# SIM3U167_B register map
File version: 1
CPU: 
Registers are 32-bit, read-write, reset 0x0 unless marked. A register's access mark holds for its fields unless they carry their own. Offsets are from the block's base; [hi:lo] are bit positions; {n}, {i} and the like mark numbered series.

## I2C_0
Base 0x40009000
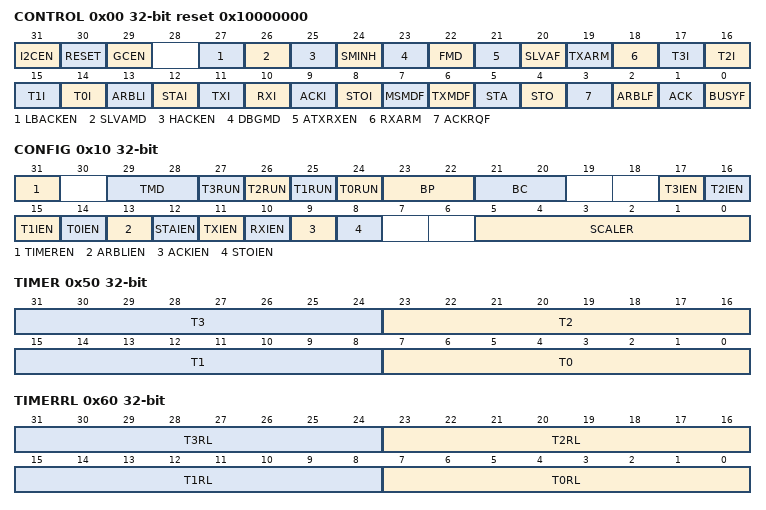
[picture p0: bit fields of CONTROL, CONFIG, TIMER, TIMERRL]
0x00 CONTROL reset 0x10000000 — Module Control
  [31] I2CEN — I2C Enable.
    0=DISABLED (Disable the I2C module.); 1=ENABLED (Enable the I2C module.)
  [30] RESET — Module Soft Reset.
    0=INACTIVE (I2C module is not in soft reset.); 1=ACTIVE (I2C module is in soft reset and firmware cannot access all bits in the module.)
  [29] GCEN — General Call Address Enable.
    0=DISABLED (Disable General Call address decoding.); 1=ENABLED (Enable General Call address decoding.)
  [27] LBACKEN — Last Byte Acknowledge Enable.
    0=DISABLED (NACK after the last byte is received.); 1=ENABLED (ACK after the last byte is received.)
  [26] SLVAMD — Slave Address Mode.
    0=7BIT (Slave addresses are 7 bits.); 1=10BIT (Slave addresses are 10 bits.)
  [25] HACKEN — Auto Acknowledge Enable .
    0=DISABLED (Disable automatic hardware acknowledge.); 1=ENABLED (Enable automatic hardware acknowledge.)
  [24] SMINH — Slave Mode Inhibit.
    0=INACTIVE (Enable Slave modes.); 1=ACTIVE (Inhibit Slave modes. The module will not respond to a Master on the bus.)
  [23] DBGMD — I2C Debug Mode.
    0=RUN (The I2C module will continue to operate while the core is halted in debug mode.); 1=HALT (A debug breakpoint will cause the I2C module to halt.)
  [22] FMD — Filter Mode.
    0=DISABLED (Disable the input filter.); 1=ENABLED (Enable the input filter.)
  [21] ATXRXEN — Auto Transmit or Receive Enable.
    0=DISABLED (Do not automatically switch to transmit or receive mode after a Start.); 1=ENABLED (If automatic hardware acknowledge mode is enabled (HACKEN = 1), automatically switch to transmit or receive mode after a Start.)
  [20] SLVAF ro — Slave Address Type Flag.
    0=SLAVE_ADDRESS (Slave address detected.); 1=GENERAL_CALL (General Call address detected.)
  [19] TXARM — Transmit Arm.
    0=DISABLED (Disable data and address transmission.); 1=ENABLED (Enable the module to perform a transmit operation.)
  [18] RXARM — Receive Arm.
    0=DISABLED (Disable data and address reception.); 1=ENABLED (Enable the module to perform a receive operation.)
  [17] T3I — I2C Timer Byte 3 Interrupt Flag.
    0=NOT_SET (Read: A I2C Timer Byte 3 interrupt or SCL low timeout has not occurred. Write: Clear the I2C Timer Byte 3 interrupt (T3I).); 1=SET (Read: I2C Timer Byte 3 overflow or SCL low timeout interrupt detected. Write: Force a I2C Timer Byte 3 interrupt.)
  [16] T2I — I2C Timer Byte 2 Interrupt Flag.
    0=NOT_SET (Read: A I2C Timer Byte 2 interrupt has not occurred. Write: Clear the I2C Timer Byte 2 interrupt (T2I).); 1=SET (Read: I2C Timer Byte 2 overflow interrupt detected. Write: Force a I2C Timer Byte 2 interrupt.)
  [15] T1I — I2C Timer Byte 1 Interrupt Flag.
    0=NOT_SET (Read: No interrupt occurred. Write: Clear the I2C Timer Byte 1 interrupt (T1I).); 1=SET (Read: I2C Timer Byte 1 overflow interrupt is detected. Write: Force a I2C Timer Byte 1 interrupt.)
  [14] T0I — I2C Timer Byte 0 Interrupt Flag.
    0=NOT_SET (Read: A I2C Timer Byte 0 interrupt has not occurred. Write: Clear the I2C Timer Byte 0 interrupt (T0I).); 1=SET (Read: I2C Timer Byte 0 overflow interrupt detected. Write: Force a I2C Timer Byte 0 interrupt.)
  [13] ARBLI — Arbitration Lost Interrupt Flag.
    0=NOT_SET (Read: An arbitration lost interrupt has not occurred. Write: Clear the arbitration lost interrupt (ARBLI).); 1=SET (Read: Arbitration lost interrupt detected. Write: Force an arbitration lost interrupt.)
  [12] STAI — Start Interrupt Flag.
    0=NOT_SET (Read: Start interrupt has not occurred. Write: Clear the start interrupt (STAI).); 1=SET (Read: Start or repeat start interrupt occurred. In Slave mode, a start or repeat start is detected. In Master mode, a start or repeat start has been generated.)
  [11] TXI — Transmit Done Interrupt Flag.
    0=NOT_SET (Read: A transmit done interrupt has not occurred. Write: Clear the transmit done interrupt (TXI).); 1=SET (Read: Transmit done interrupt detected. If the transmit is forced to abort by a NACK response, the acknowledge interrupt (ACKI) will also be set. Write: Force a transmit done interrupt.)
  [10] RXI — Receive Done Interrupt Flag.
    0=NOT_SET (Read: A receive done interrupt has not occurred. Write: Clear the receive done interrupt (RXI).); 1=SET (Read: Receive done interrupt occurred. Write: Force a receive done interrupt.)
  [9] ACKI — Acknowledge Interrupt Flag.
    0=NOT_SET (Read: An acknowledge interrupt has not occurred. Write: Clear the acknowledge interrupt (ACKI).); 1=SET (Read: An acknowledge interrupt occurred. Write: Force an acknowledge interrupt.)
  [8] STOI — Stop Interrupt Flag.
    0=NOT_SET (Read: A stop interrupt has not occurred. Write: Clear the stop interrupt flag (STOI).); 1=SET (Read: Stop interrupt detected. In Slave mode, a stop has been detected on the bus. In Master mode, a stop has been generated. Write: Force a stop interrupt.)
  [7] MSMDF ro — Master/Slave Mode Flag.
    0=SLAVE (Module is operating in Slave mode.); 1=MASTER (Module is operating in Master mode.)
  [6] TXMDF ro — Transmit Mode Flag.
    0=RECEIVE (Module is in receiver mode.); 1=TRANSMIT (Module is in transmitter mode.)
  [5] STA — Start.
    0=NOT_SET (Read: A start is not pending and a repeat start has not been detected. Write: Clear the STA bit.); 1=SET (Read: Start or repeat start detected. This bit must be cleared by firmware. Write: Generate a start or repeat start.)
  [4] STO — Stop.
    0=NOT_SET (Read: A stop is not pending and a stop / repeat start has not been detected. Write: Clear the STO bit.); 1=SET (Read: Stop or stop / repeat start detected. This bit must be cleared by firmware. Write: Generate a stop.)
  [3] ACKRQF ro — Acknowledge Request Flag.
    0=NOT_SET (ACK has not been requested.); 1=SET (ACK requested.)
  [2] ARBLF ro — Arbitration Lost Flag.
    0=NOT_SET (Arbitration lost error has not occurred.); 1=SET (Arbitration lost error occurred.)
  [1] ACK — Acknowledge.
    0=NOT_SET (Read: ACK has not been received. Write: Do not send an ACK.); 1=SET (Read: ACK received. Write: Send an ACK.)
  [0] BUSYF ro — Busy Flag.
    0=NOT_SET (A transaction is not currently taking place.); 1=SET (A transaction is currently taking place.)
0x10 CONFIG — Module Configuration
  [31] TIMEREN — I2C Timer Enable.
    0=DISABLED (Disable I2C Timer.); 1=ENABLED (Enable I2C Timer for general purpose use. This setting should not be used when the I2C module is enabled (I2CEN = 1).)
  [29:28] TMD — I2C Timer Mode.
    0=MODE0 (I2C Timer Mode 0: Operate the I2C timer as a single 32-bit timer : Timer Bytes [3 : 2 : 1 : 0].); 1=MODE1 (I2C Timer Mode 1: Operate the I2C timer as two 16-bit timers : Timer Bytes [3 : 2] and Timer Bytes [1 : 0].); 2=MODE2 (I2C Timer Mode 2: Operate the I2C timer as four independent 8-bit timers : Timer Byte 3, Timer Byte 2, Timer Byte 1, and Timer Byte 0.); 3=MODE3 (I2C Timer Mode 3: Operate the I2C timer as one 16-bit and two 8-bit timers : Timer Bytes [3 : 2], Timer Byte 1, and Timer Byte 0.)
  [n+24] T{n}RUN (n=0..3) — I2C Timer Byte {n} Run.
    0=STOP (Stop Timer Byte {n}.); 1=START (Start Timer Byte {n} running.)
  [23:22] BP ro — Transfer Byte Pointer.
  [21:20] BC — Transfer Byte Count.
  [17] T3IEN — I2C Timer Byte 3 Interrupt Enable.
    0=DISABLED (Disable the I2C Timer Byte 3 and SCL low timeout interrupt.); 1=ENABLED (Enable the I2C Timer Byte 3 and SCL low timeout interrupt (T3I).)
  [16] T2IEN — I2C Timer Byte 2 Interrupt Enable.
    0=DISABLED (Disable the I2C Timer Byte 2 interrupt.); 1=ENABLED (Enable the I2C Timer Byte 2 interrupt (T2I).)
  [15] T1IEN — I2C Timer Byte 1 Interrupt Enable.
    0=DISABLED (Disable the I2C Timer Byte 1 interrupt.); 1=ENABLED (Enable the I2C Timer Byte 1 interrupt (T1I).)
  [14] T0IEN — I2C Timer Byte 0 Interrupt Enable.
    0=DISABLED (Disable the I2C Timer Byte 0 interrupt.); 1=ENABLED (Enable the I2C Timer Byte 0 interrupt (T0I).)
  [13] ARBLIEN — Arbitration Lost Interrupt Enable.
    0=DISABLED (Disable the arbitration lost interrupt.); 1=ENABLED (Enable the arbitration lost interrupt (ARBLI).)
  [12] STAIEN — Start Interrupt Enable.
    0=DISABLED (Disable the start interrupt.); 1=ENABLED (Enable the start interrupt (STAI).)
  [11] TXIEN — Transmit Done Interrupt Enable.
    0=DISABLED (Disable the transmit done interrupt.); 1=ENABLED (Enable the transmit done interrupt (TXI).)
  [10] RXIEN — Receive Done Interrupt Enable.
    0=DISABLED (Disable the receive done interrupt.); 1=ENABLED (Enable the receive done interrupt (RXI).)
  [9] ACKIEN — Acknowledge Interrupt Enable.
    0=DISABLED (Disable the acknowledge interrupt.); 1=ENABLED (Enable the acknowledge interrupt (ACKI).)
  [8] STOIEN — Stop Interrupt Enable.
    0=DISABLED (Disable the stop interrupt.); 1=ENABLED (Enable the stop interrupt (STOI).)
  [5:0] SCALER — I2C Clock Scaler.
0x20 SADDRESS — Slave Address
  [10:1] ADDRESS — Slave Address.
0x30 SMASK — Slave Address Mask
  [10:1] MASK — Slave Address Mask.
0x40 DATA — Data Buffer Access
0x50 TIMER — Timer Data
  [8n+7:8n] T{n} (n=0..3) — Timer Byte {n}.
0x60 TIMERRL — Timer Reload Values
  [8n+7:8n] T{n}RL (n=0..3) — Timer Byte {n} Reload Value.
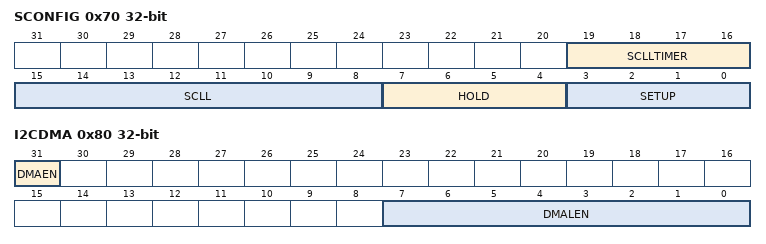
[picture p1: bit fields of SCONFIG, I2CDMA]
0x70 SCONFIG — SCL Signal Configuration
  [19:16] SCLLTIMER ro — SCL Low Timer Bits [3:0].
  [15:8] SCLL — SCL Low Time Extension.
  [7:4] HOLD — Data Hold Time Extension.
  [3:0] SETUP — Data Setup Time Extension.
0x80 I2CDMA — DMA Configuration
  [31] DMAEN — DMA Mode Enable.
    0=DISABLED (Disable I2C DMA data requests.); 1=ENABLED (Enable I2C DMA data requests.)
  [7:0] DMALEN — DMA Transfer Length.

## I2C_1
Base 0x4000A000
Registers as I2C_0, without I2CDMA.
